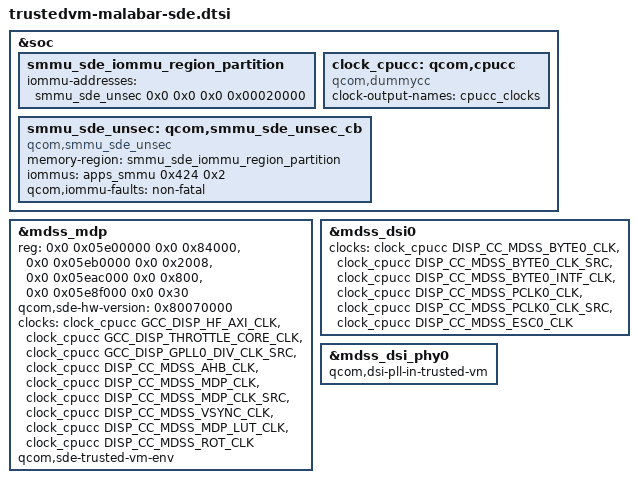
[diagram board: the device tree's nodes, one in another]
// SPDX-License-Identifier: BSD-3-Clause
/*
 * Copyright (c) Qualcomm Technologies, Inc. and/or its subsidiaries.
 */

#include <dt-bindings/clock/qcom,malabar-dispcc.h>
#include <dt-bindings/clock/qcom,malabar-gcc.h>
#include "malabar-sde-common.dtsi"
#include "trustedvm-malabar-avf-required-subnodes.dtsi"

&soc {
	smmu_sde_iommu_region_partition: smmu_sde_iommu_region_partition {
		iommu-addresses = <&smmu_sde_unsec 0x0 0x0 0x0 0x00020000>;
	};

	/* dummy display clock provider */
	clock_cpucc: qcom,cpucc {
		compatible = "qcom,dummycc";
		clock-output-names = "cpucc_clocks";
		#clock-cells = <1>;
	};

	smmu_sde_unsec: qcom,smmu_sde_unsec_cb {
		compatible = "qcom,smmu_sde_unsec";
		memory-region = <&smmu_sde_iommu_region_partition>;
		iommus = <&apps_smmu 0x424 0x2>;
		qcom,iommu-faults = "non-fatal";
	};
};

&mdss_mdp {
	#address-cells = <2>;
	#size-cells = <2>;
	reg = <0x0 0x05e00000 0x0 0x84000>,
		<0x0 0x05eb0000 0x0 0x2008>,
		<0x0 0x05eac000 0x0 0x800>,
		<0x0 0x05e8f000 0x0 0x30>;

	reg-names = "mdp_phys",
		"vbif_phys",
		"regdma_phys",
		"sid_phys";

	qcom,sde-hw-version =<0x80070000>;

	clocks =
		<&clock_cpucc GCC_DISP_HF_AXI_CLK>,
		<&clock_cpucc GCC_DISP_THROTTLE_CORE_CLK>,
		<&clock_cpucc GCC_DISP_GPLL0_DIV_CLK_SRC>,
		<&clock_cpucc DISP_CC_MDSS_AHB_CLK>,
		<&clock_cpucc DISP_CC_MDSS_MDP_CLK>,
		<&clock_cpucc DISP_CC_MDSS_MDP_CLK_SRC>,
		<&clock_cpucc DISP_CC_MDSS_VSYNC_CLK>,
		<&clock_cpucc DISP_CC_MDSS_MDP_LUT_CLK>,
		<&clock_cpucc DISP_CC_MDSS_ROT_CLK>;

	clock-names = "gcc_bus", "throttle_clk", "div_clk", "iface_clk",
			"branch_clk", "core_clk", "vsync_clk",
			"lut_clk", "rot_clk";
	qcom,sde-trusted-vm-env;
};

&mdss_dsi0 {
	clocks = <&clock_cpucc DISP_CC_MDSS_BYTE0_CLK>,
		<&clock_cpucc DISP_CC_MDSS_BYTE0_CLK_SRC>,
		<&clock_cpucc DISP_CC_MDSS_BYTE0_INTF_CLK>,
		<&clock_cpucc DISP_CC_MDSS_PCLK0_CLK>,
		<&clock_cpucc DISP_CC_MDSS_PCLK0_CLK_SRC>,
		<&clock_cpucc DISP_CC_MDSS_ESC0_CLK>;
	clock-names = "byte_clk", "byte_clk_rcg", "byte_intf_clk",
			"pixel_clk", "pixel_clk_rcg", "esc_clk";
};

&mdss_dsi_phy0 {
	qcom,dsi-pll-in-trusted-vm;
};
